VERSION ""

NS_ :

BS_:

BU_: Gateway ESC EPS ADAS Cluster

BO_ 288 VehicleDynamics: 16 ESC
 SG_ VehicleSpeed : 0|16@1+ (0.01,0) [0|300] "km/h" Gateway,ADAS
 SG_ YawRate : 16|16@1- (0.01,0) [-100|100] "deg/s" Gateway,ADAS
 SG_ LongitudinalAccel : 32|16@1- (0.01,0) [-20|20] "m/s2" Gateway,ADAS
 SG_ LateralAccel : 48|16@1- (0.01,0) [-20|20] "m/s2" Gateway,ADAS

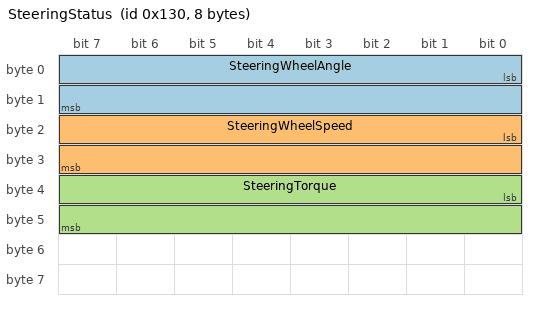
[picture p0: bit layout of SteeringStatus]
BO_ 304 SteeringStatus: 8 EPS
 SG_ SteeringWheelAngle : 0|16@1- (0.1,0) [-720|720] "deg" Gateway,ESC
 SG_ SteeringWheelSpeed : 16|16@1+ (1,0) [0|1000] "deg/s" Gateway,ESC
 SG_ SteeringTorque : 32|16@1- (0.1,0) [-20|20] "Nm" Gateway

CM_ BO_ 288 "Electronic Stability Control active dynamics broadcast at 10ms cycle time on CAN FD.";
CM_ SG_ 288 VehicleSpeed "Filtered vehicle ground speed derived from four-wheel speed sensors.";
CM_ SG_ 288 YawRate "Inertial measurement unit angular velocity around Z-axis.";
CM_ BO_ 304 "Electronic Power Steering angle and driver torque feedback.";
